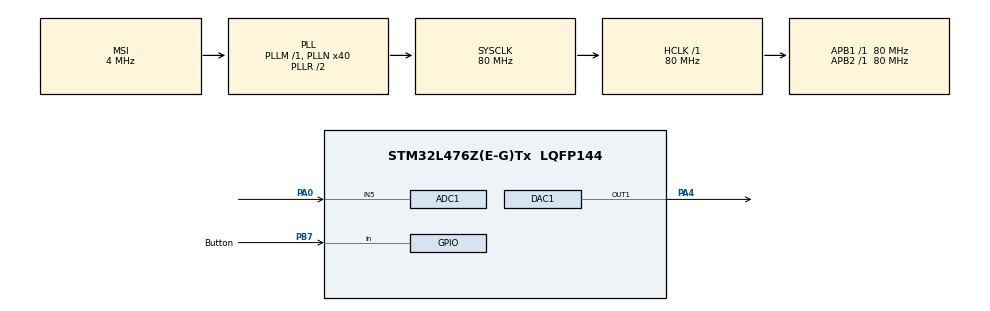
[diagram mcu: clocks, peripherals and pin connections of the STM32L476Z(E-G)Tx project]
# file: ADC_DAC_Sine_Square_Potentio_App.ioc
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ADC1.Channel-0\#ChannelRegularConversion=ADC_CHANNEL_5
ADC1.NbrOfConversionFlag=1
ADC1.OffsetNumber-0\#ChannelRegularConversion=ADC_OFFSET_NONE
ADC1.Rank-0\#ChannelRegularConversion=1
ADC1.SamplingTime-0\#ChannelRegularConversion=ADC_SAMPLETIME_2CYCLES_5
ADC1.master=1
DAC1.DAC_Trigger-DAC_OUT1_ExtAndInt=DAC_TRIGGER_T2_TRGO
Mcu.Family=STM32L4
Mcu.Name=STM32L476Z(E-G)Tx
Mcu.Package=LQFP144
NVIC.PriorityGroup=NVIC_PRIORITYGROUP_4
NVIC.TIM2_IRQn=true\:0\:0\:false\:false\:true\:true\:true\:true
PA0.Signal=ADCx_IN5
PA13\ (JTMS-SWDIO).Mode=Serial_Wire
PA13\ (JTMS-SWDIO).Signal=SYS_JTMS-SWDIO
PA14\ (JTCK-SWCLK).Mode=Serial_Wire
PA14\ (JTCK-SWCLK).Signal=SYS_JTCK-SWCLK
PA4.Signal=COMP_DAC11_group
PB7.GPIO_Label=Button
PB7.GPIO_PuPd=GPIO_PULLUP
PB7.Signal=GPIO_Input
PC14-OSC32_IN\ (PC14).Mode=LSE-External-Oscillator
PC14-OSC32_IN\ (PC14).Signal=RCC_OSC32_IN
PC15-OSC32_OUT\ (PC15).Mode=LSE-External-Oscillator
PC15-OSC32_OUT\ (PC15).Signal=RCC_OSC32_OUT
PH0-OSC_IN\ (PH0).Mode=HSE-External-Oscillator
PH0-OSC_IN\ (PH0).Signal=RCC_OSC_IN
PH1-OSC_OUT\ (PH1).Mode=HSE-External-Oscillator
PH1-OSC_OUT\ (PH1).Signal=RCC_OSC_OUT
ProjectManager.HeapSize=0x200
ProjectManager.StackSize=0x400
ProjectManager.TargetToolchain=STM32CubeIDE
RCC.ADCFreq_Value=32000000
RCC.AHBFreq_Value=80000000
RCC.APB1Freq_Value=80000000
RCC.APB1TimFreq_Value=80000000
RCC.APB2Freq_Value=80000000
RCC.APB2TimFreq_Value=80000000
RCC.CortexFreq_Value=80000000
RCC.HCLKFreq_Value=80000000
RCC.HSE_VALUE=8000000
RCC.HSI_VALUE=16000000
RCC.MSI_VALUE=4000000
RCC.PLLN=40
RCC.PLLSAI1N=16
RCC.SYSCLKFreq_VALUE=80000000
RCC.SYSCLKSource=RCC_SYSCLKSOURCE_PLLCLK
RCC.USBFreq_Value=32000000
RCC.VCOOutputFreq_Value=160000000
SH.ADCx_IN5.0=ADC1_IN5,IN5-Single-Ended
SH.COMP_DAC11_group.0=DAC1_OUT1,DAC_OUT1_ExtAndInt
TIM2.Period=100-1
TIM2.Prescaler=80-1
TIM2.TIM_MasterOutputTrigger=TIM_TRGO_UPDATE
VP_TIM2_VS_ClockSourceINT.Mode=Internal
board=custom

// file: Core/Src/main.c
/* USER CODE BEGIN Header */
/**
  ******************************************************************************
  * @file           : main.c
  * @brief          : Main program body
  ******************************************************************************
  * @attention
  *
  * Copyright (c) 2024 STMicroelectronics.
  * All rights reserved.
  *
  * This software is licensed under terms that can be found in the LICENSE file
  * in the root directory of this software component.
  * If no LICENSE file comes with this software, it is provided AS-IS.
  *
  ******************************************************************************
  */
/* USER CODE END Header */
#include "main.h"

/* USER CODE BEGIN Includes */
#include "math.h"
/* USER CODE END Includes */

ADC_HandleTypeDef hadc1;

DAC_HandleTypeDef hdac1;

TIM_HandleTypeDef htim2;

void SystemClock_Config(void);
static void MX_GPIO_Init(void);
static void MX_DAC1_Init(void);
static void MX_TIM2_Init(void);
static void MX_ADC1_Init(void);

/* USER CODE BEGIN 0 */
#define SAMPLES 100
uint16_t square_val[SAMPLES];
uint16_t  sine_val[SAMPLES];
#define PI   3.1415926
uint32_t adc_value = 0;
//uint8_t waveform_flag = 0;    // 0 = Sine wave, 1 = Square wave
//uint8_t button_pressed  = 0;     // Button state for toggling
volatile uint8_t sine_flag = 1;   // Flag to enable sine wave
volatile uint8_t square_flag = 0; // Flag to enable square wave
void get_sineval(void)
{
	for (int i =0; i<SAMPLES; i++){
		sine_val[i] = (uint16_t) ((sin(i*2*PI/SAMPLES) + 1)*(4096/2));
	}
}
void get_squareval(void) // Generating Square wave
{
	for (int i = 0; i < SAMPLES; i++) {
		square_val[i] = (i < SAMPLES / 2) ? (4096 / 2) : 0;
	    }
}
void Toggle_Waveform(void) {
    if (sine_flag) {
        sine_flag = 0;
        square_flag = 1;
    } else {
        square_flag = 0;
        sine_flag = 1;
    }
}
void HAL_TIM_PeriodElapsedCallback(TIM_HandleTypeDef *htim) {
    static uint8_t index = 0;

    if (htim->Instance == TIM2) {
        if (sine_flag) {
            // Output sine wave sample
            HAL_DAC_SetValue(&hdac1, DAC_CHANNEL_1, DAC_ALIGN_12B_R, sine_val[index]);
        } else if (square_flag) {
            // Output square wave sample
            HAL_DAC_SetValue(&hdac1, DAC_CHANNEL_1, DAC_ALIGN_12B_R, square_val[index]);
        }
        // Increment index and wrap around
        index = (index + 1) % SAMPLES;
    }
}
//void Output_SineWave(void) {
//    static uint8_t index = 0;
//
//    if (__HAL_TIM_GET_FLAG(&htim2, TIM_FLAG_UPDATE)) { // Timer period elapsed
//        __HAL_TIM_CLEAR_FLAG(&htim2, TIM_FLAG_UPDATE); // Clear the flag
//        HAL_DAC_SetValue(&hdac1, DAC_CHANNEL_1, DAC_ALIGN_12B_R, sine_val[index]);
//        index = (index + 1) % SAMPLES; // Increment index and wrap around
//    }
//}
//void Output_SquareWave(void) {
//    static uint8_t index = 0;
//
//    if (__HAL_TIM_GET_FLAG(&htim2, TIM_FLAG_UPDATE)) { // Timer period elapsed
//        __HAL_TIM_CLEAR_FLAG(&htim2, TIM_FLAG_UPDATE); // Clear the flag
//        HAL_DAC_SetValue(&hdac1, DAC_CHANNEL_1, DAC_ALIGN_12B_R, square_val[index]);
//        index = (index + 1) % SAMPLES; // Increment index and wrap around
//    }
//}
//void HAL_GPIO_EXTI_Callback(uint16_t GPIO_Pin) {
//    if (GPIO_Pin == Button_Pin) {
//        button_pressed = 1; // Set button press flag
//    }
//}
//uint8_t Read_Button(void)
//{
//	static uint8_t prev_state = 1; // Button State (not pressed)
//	uint8_t current_state = HAL_GPIO_ReadPin(Button_GPIO_Port, Button_Pin);
//	if (prev_state == 1 && current_state == 0) {       // Detect falling edge
//	        HAL_Delay(100);                           // Debounce delay
//	        if (HAL_GPIO_ReadPin(Button_GPIO_Port, Button_Pin) == 0) {
//	            prev_state = 0;
//	            return 1;                              // Button pressed
//	        }
//	    } else if (current_state == 1) {
//	        prev_state = 1;                           // Button not pressed
//	    }
//	    return 0;                                     // No button press detected
//
//}
//void Toggle_Waveform(void) {
//    waveform_flag = !waveform_flag; // Toggle between 0 and 1
//}
//void HAL_TIM_PeriodElapsedCallback(TIM_HandleTypeDef *htim) {
//    static uint8_t sample_index = 0;
//
//    if (htim->Instance == TIM2) {
//        if (waveform_flag == 0) {
//            // Output sine wave
//            HAL_DAC_SetValue(&hdac1, DAC_CHANNEL_1, DAC_ALIGN_12B_R, sine_val[sample_index]);
//        } else {
//            // Output square wave
//            HAL_DAC_SetValue(&hdac1, DAC_CHANNEL_1, DAC_ALIGN_12B_R, square_val[sample_index]);
//        }
//        sample_index = (sample_index + 1) % 100; // Increment and wrap index
//    }
//}
/* USER CODE END 0 */

int main(void)
{

  /* MCU Configuration--------------------------------------------------------*/

  /* Reset of all peripherals, Initializes the Flash interface and the Systick. */
  HAL_Init();

  /* Configure the system clock */
  SystemClock_Config();

  /* Initialize all configured peripherals */
  MX_GPIO_Init();
  MX_DAC1_Init();
  MX_TIM2_Init();
  MX_ADC1_Init();
  /* USER CODE BEGIN 2 */
//HAL_DAC_Start(&hdac1, DAC_CHANNEL_1);
//  HAL_TIM_Base_Start(&htim2);
  get_sineval();
//  HAL_DAC_Start_DMA(&hdac1, DAC_CHANNEL_1, sine_val, 100, DAC_ALIGN_12B_R);

//  HAL_TIM_Base_Start(&htim2);
  get_squareval();
  HAL_DAC_Start(&hdac1, DAC_CHANNEL_1);
  HAL_TIM_Base_Start_IT(&htim2);
//    uint8_t index = 0; // Current index of the sine wave
//   HAL_DAC_Start_DMA(&hdac1, DAC_CHANNEL_1, square_val, 100, DAC_ALIGN_12B_R);
  //waveform_flag = 3;
  /* USER CODE END 2 */

  /* Infinite loop */
  /* USER CODE BEGIN WHILE */
  while (1)
  {
	  // Check if the timer has elapsed
//	        if (__HAL_TIM_GET_FLAG(&htim2, TIM_FLAG_UPDATE)) {
//	            __HAL_TIM_CLEAR_FLAG(&htim2, TIM_FLAG_UPDATE); // Clear the flag
//
//	            // Set DAC value with the current sine wave sample
//	            HAL_DAC_SetValue(&hdac1, DAC_CHANNEL_1, DAC_ALIGN_12B_R, sine_val[index]);
//
//	            // Increment index and wrap around when the end of the array is reached
//	            index = (index + 1) % SAMPLES;
//	        }

	  ///////////////////////////////////////////

	  HAL_ADC_Start(&hadc1);  // Reading ADC value
	  if(HAL_ADC_PollForConversion(&hadc1, 1000) == HAL_OK)
		{
		  adc_value = HAL_ADC_GetValue(&hadc1);
	  }
	  HAL_ADC_Stop(&hadc1);
	  if (HAL_GPIO_ReadPin(Button_GPIO_Port, Button_Pin) == GPIO_PIN_RESET) { // Button pressed
	              HAL_Delay(100); // Debounce delay
	              if (HAL_GPIO_ReadPin(Button_GPIO_Port, Button_Pin) == GPIO_PIN_RESET) {
	                  Toggle_Waveform();
	                  while (HAL_GPIO_ReadPin(Button_GPIO_Port, Button_Pin) == GPIO_PIN_RESET); // Wait for button release
	              }
	          }

//	  // Output the appropriate waveform
//	          if (sine_flag) {
//	        	  Output_SineWave();
//	          } else if (square_flag) {
//	              Output_SquareWave();
//	          }

//	  if (HAL_GPIO_ReadPin(Button_GPIO_Port, Button_Pin) == 0) {
//	      HAL_GPIO_TogglePin(LED_GPIO_Port, LED_Pin); // Toggle LED
//	  }
//	  if (button_pressed) {
//	              button_pressed = 0; // Reset flag
//	              Toggle_Waveform();  // Toggle the waveform
//	          }

//	  if (Read_Button())
//	    {
//		  //waveform_flag = !waveform_flag; // Toggle waveform flag
//		  waveform_flag = 1;
//	    }
//	        if (waveform_flag == 1){
//	        	HAL_TIM_Base_Start(&htim2);
//	        	get_squareval();
//	        HAL_DAC_Start_DMA(&hdac1, DAC_CHANNEL_1, square_val, 100, DAC_ALIGN_12B_R);
//	        HAL_Delay(5000);
//	        waveform_flag = 3;
//	        }else if (waveform_flag == 0){
//	        	HAL_TIM_Base_Start(&htim2);
//	        get_sineval();
//	      HAL_DAC_Start_DMA(&hdac1, DAC_CHANNEL_1, sine_val, 100, DAC_ALIGN_12B_R);
//	      waveform_flag = 3;
//	        }

    /* USER CODE END WHILE */

  }
}

void SystemClock_Config(void)
{
  RCC_OscInitTypeDef RCC_OscInitStruct = {0};
  RCC_ClkInitTypeDef RCC_ClkInitStruct = {0};

  /** Configure the main internal regulator output voltage
  */
  if (HAL_PWREx_ControlVoltageScaling(PWR_REGULATOR_VOLTAGE_SCALE1) != HAL_OK)
  {
    Error_Handler();
  }

  /** Configure LSE Drive Capability
  */
  HAL_PWR_EnableBkUpAccess();
  __HAL_RCC_LSEDRIVE_CONFIG(RCC_LSEDRIVE_LOW);

  /** Initializes the RCC Oscillators according to the specified parameters
  * in the RCC_OscInitTypeDef structure.
  */
  RCC_OscInitStruct.OscillatorType = RCC_OSCILLATORTYPE_LSE|RCC_OSCILLATORTYPE_MSI;
  RCC_OscInitStruct.LSEState = RCC_LSE_ON;
  RCC_OscInitStruct.MSIState = RCC_MSI_ON;
  RCC_OscInitStruct.MSICalibrationValue = 0;
  RCC_OscInitStruct.MSIClockRange = RCC_MSIRANGE_6;
  RCC_OscInitStruct.PLL.PLLState = RCC_PLL_ON;
  RCC_OscInitStruct.PLL.PLLSource = RCC_PLLSOURCE_MSI;
  RCC_OscInitStruct.PLL.PLLM = 1;
  RCC_OscInitStruct.PLL.PLLN = 40;
  RCC_OscInitStruct.PLL.PLLP = RCC_PLLP_DIV7;
  RCC_OscInitStruct.PLL.PLLQ = RCC_PLLQ_DIV2;
  RCC_OscInitStruct.PLL.PLLR = RCC_PLLR_DIV2;
  if (HAL_RCC_OscConfig(&RCC_OscInitStruct) != HAL_OK)
  {
    Error_Handler();
  }

  /** Initializes the CPU, AHB and APB buses clocks
  */
  RCC_ClkInitStruct.ClockType = RCC_CLOCKTYPE_HCLK|RCC_CLOCKTYPE_SYSCLK
                              |RCC_CLOCKTYPE_PCLK1|RCC_CLOCKTYPE_PCLK2;
  RCC_ClkInitStruct.SYSCLKSource = RCC_SYSCLKSOURCE_PLLCLK;
  RCC_ClkInitStruct.AHBCLKDivider = RCC_SYSCLK_DIV1;
  RCC_ClkInitStruct.APB1CLKDivider = RCC_HCLK_DIV1;
  RCC_ClkInitStruct.APB2CLKDivider = RCC_HCLK_DIV1;

  if (HAL_RCC_ClockConfig(&RCC_ClkInitStruct, FLASH_LATENCY_4) != HAL_OK)
  {
    Error_Handler();
  }

  /** Enable MSI Auto calibration
  */
  HAL_RCCEx_EnableMSIPLLMode();
}

static void MX_ADC1_Init(void)
{

  ADC_MultiModeTypeDef multimode = {0};
  ADC_ChannelConfTypeDef sConfig = {0};

  /** Common config
  */
  hadc1.Instance = ADC1;
  hadc1.Init.ClockPrescaler = ADC_CLOCK_ASYNC_DIV1;
  hadc1.Init.Resolution = ADC_RESOLUTION_12B;
  hadc1.Init.DataAlign = ADC_DATAALIGN_RIGHT;
  hadc1.Init.ScanConvMode = ADC_SCAN_DISABLE;
  hadc1.Init.EOCSelection = ADC_EOC_SINGLE_CONV;
  hadc1.Init.LowPowerAutoWait = DISABLE;
  hadc1.Init.ContinuousConvMode = DISABLE;
  hadc1.Init.NbrOfConversion = 1;
  hadc1.Init.DiscontinuousConvMode = DISABLE;
  hadc1.Init.ExternalTrigConv = ADC_SOFTWARE_START;
  hadc1.Init.ExternalTrigConvEdge = ADC_EXTERNALTRIGCONVEDGE_NONE;
  hadc1.Init.DMAContinuousRequests = DISABLE;
  hadc1.Init.Overrun = ADC_OVR_DATA_PRESERVED;
  hadc1.Init.OversamplingMode = DISABLE;
  if (HAL_ADC_Init(&hadc1) != HAL_OK)
  {
    Error_Handler();
  }

  /** Configure the ADC multi-mode
  */
  multimode.Mode = ADC_MODE_INDEPENDENT;
  if (HAL_ADCEx_MultiModeConfigChannel(&hadc1, &multimode) != HAL_OK)
  {
    Error_Handler();
  }

  /** Configure Regular Channel
  */
  sConfig.Channel = ADC_CHANNEL_5;
  sConfig.Rank = ADC_REGULAR_RANK_1;
  sConfig.SamplingTime = ADC_SAMPLETIME_2CYCLES_5;
  sConfig.SingleDiff = ADC_SINGLE_ENDED;
  sConfig.OffsetNumber = ADC_OFFSET_NONE;
  sConfig.Offset = 0;
  if (HAL_ADC_ConfigChannel(&hadc1, &sConfig) != HAL_OK)
  {
    Error_Handler();
  }

}

static void MX_DAC1_Init(void)
{

  DAC_ChannelConfTypeDef sConfig = {0};

  /** DAC Initialization
  */
  hdac1.Instance = DAC1;
  if (HAL_DAC_Init(&hdac1) != HAL_OK)
  {
    Error_Handler();
  }

  /** DAC channel OUT1 config
  */
  sConfig.DAC_SampleAndHold = DAC_SAMPLEANDHOLD_DISABLE;
  sConfig.DAC_Trigger = DAC_TRIGGER_T2_TRGO;
  sConfig.DAC_OutputBuffer = DAC_OUTPUTBUFFER_ENABLE;
  sConfig.DAC_ConnectOnChipPeripheral = DAC_CHIPCONNECT_ENABLE;
  sConfig.DAC_UserTrimming = DAC_TRIMMING_FACTORY;
  if (HAL_DAC_ConfigChannel(&hdac1, &sConfig, DAC_CHANNEL_1) != HAL_OK)
  {
    Error_Handler();
  }

}

static void MX_TIM2_Init(void)
{

  TIM_ClockConfigTypeDef sClockSourceConfig = {0};
  TIM_MasterConfigTypeDef sMasterConfig = {0};

  htim2.Instance = TIM2;
  htim2.Init.Prescaler = 80-1;
  htim2.Init.CounterMode = TIM_COUNTERMODE_UP;
  htim2.Init.Period = 100-1;
  htim2.Init.ClockDivision = TIM_CLOCKDIVISION_DIV1;
  htim2.Init.AutoReloadPreload = TIM_AUTORELOAD_PRELOAD_DISABLE;
  if (HAL_TIM_Base_Init(&htim2) != HAL_OK)
  {
    Error_Handler();
  }
  sClockSourceConfig.ClockSource = TIM_CLOCKSOURCE_INTERNAL;
  if (HAL_TIM_ConfigClockSource(&htim2, &sClockSourceConfig) != HAL_OK)
  {
    Error_Handler();
  }
  sMasterConfig.MasterOutputTrigger = TIM_TRGO_UPDATE;
  sMasterConfig.MasterSlaveMode = TIM_MASTERSLAVEMODE_DISABLE;
  if (HAL_TIMEx_MasterConfigSynchronization(&htim2, &sMasterConfig) != HAL_OK)
  {
    Error_Handler();
  }

}

static void MX_GPIO_Init(void)
{
  GPIO_InitTypeDef GPIO_InitStruct = {0};

  /* GPIO Ports Clock Enable */
  __HAL_RCC_GPIOC_CLK_ENABLE();
  __HAL_RCC_GPIOH_CLK_ENABLE();
  __HAL_RCC_GPIOA_CLK_ENABLE();
  __HAL_RCC_GPIOB_CLK_ENABLE();

  /*Configure GPIO pin : Button_Pin */
  GPIO_InitStruct.Pin = Button_Pin;
  GPIO_InitStruct.Mode = GPIO_MODE_INPUT;
  GPIO_InitStruct.Pull = GPIO_PULLUP;
  HAL_GPIO_Init(Button_GPIO_Port, &GPIO_InitStruct);

}

void Error_Handler(void)
{
  __disable_irq();
  while (1)
  {
  }
}
